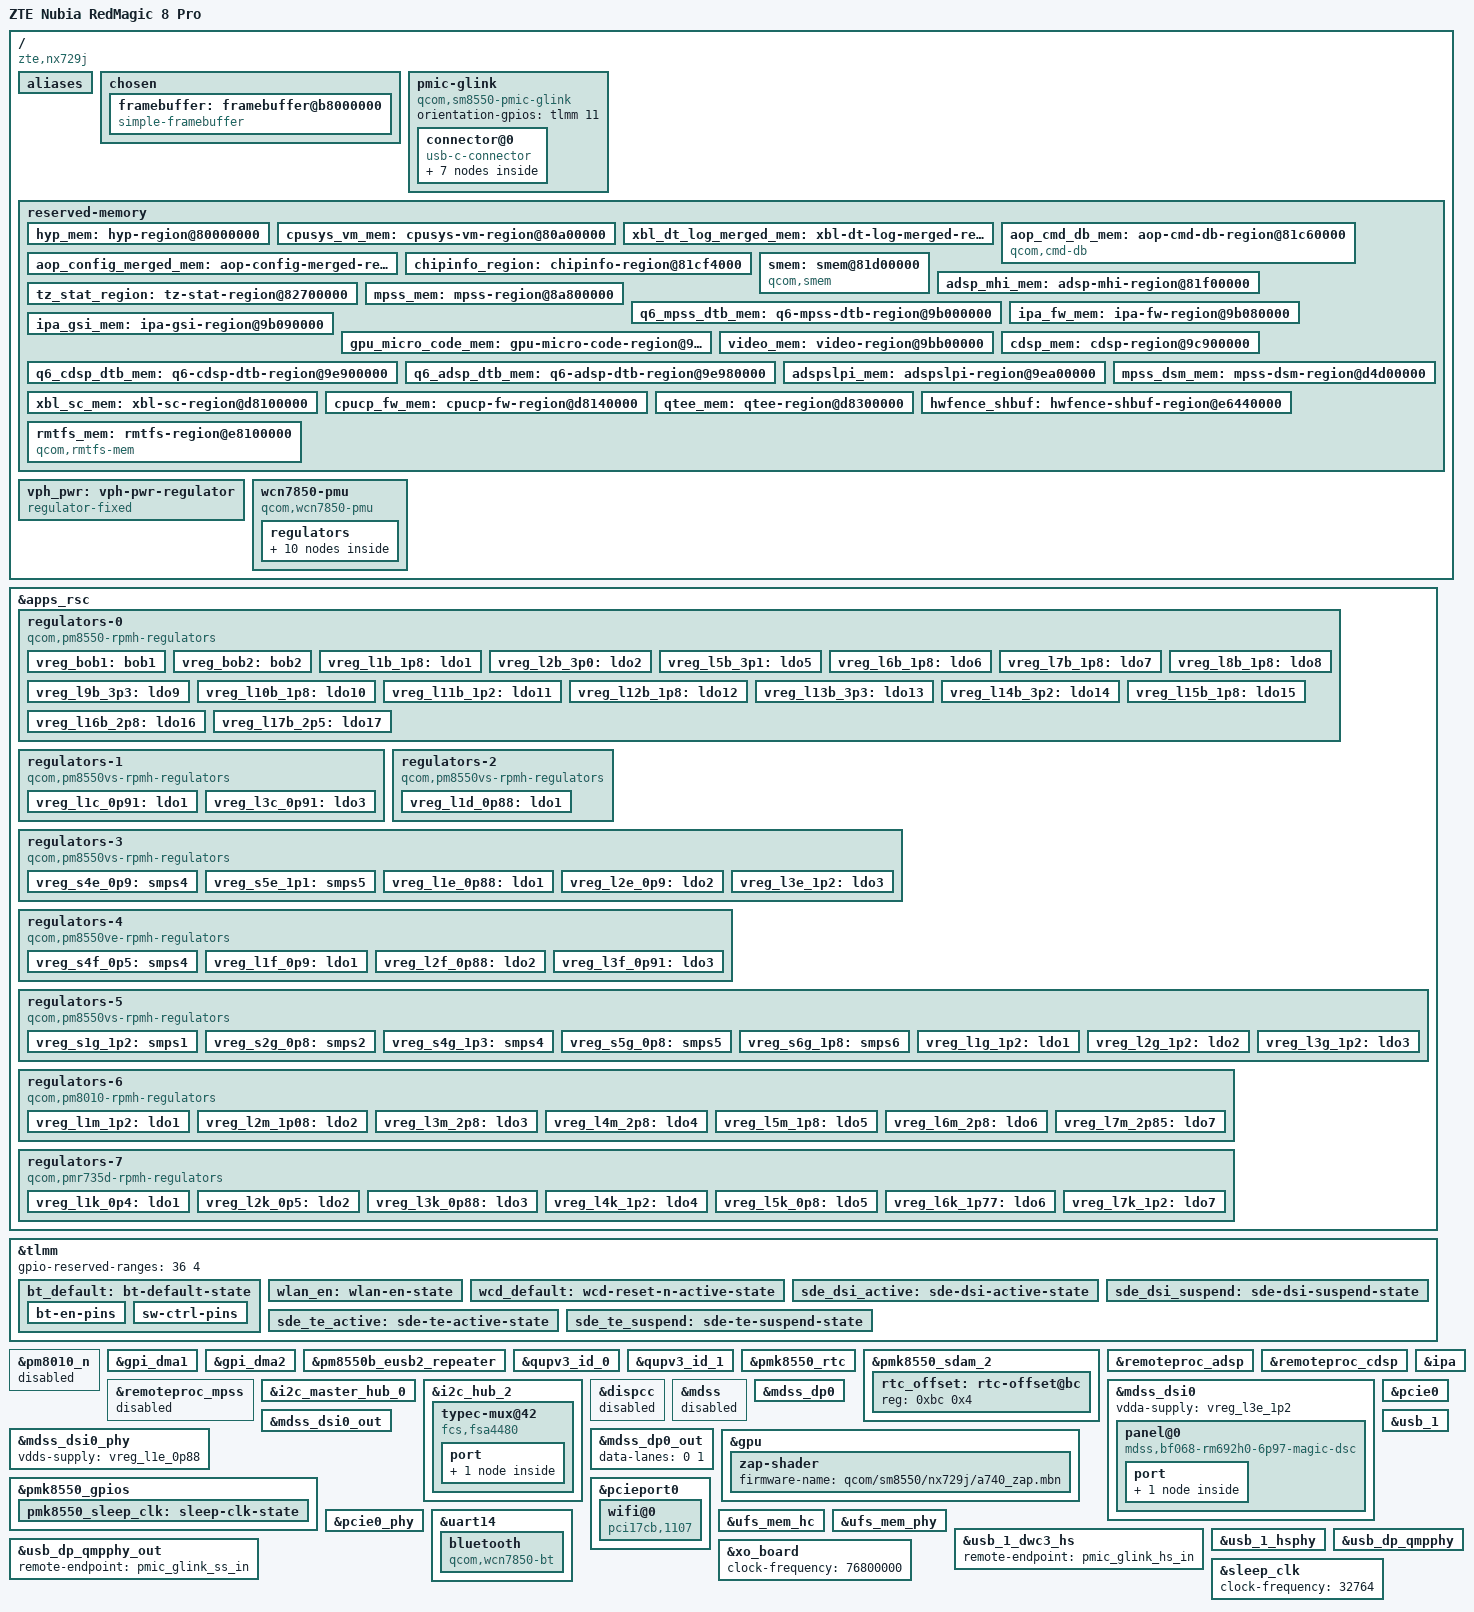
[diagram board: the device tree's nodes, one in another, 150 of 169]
// SPDX-License-Identifier: BSD-3-Clause
/*
 * Copyright (c) 2025, Nika Okromtchedlishvili <okromtchedlishvilinika@gmail.com>
 */
 
/dts-v1/;

#include <dt-bindings/arm/qcom,ids.h>
#include <dt-bindings/leds/common.h>
#include <dt-bindings/regulator/qcom,rpmh-regulator.h>
#include <dt-bindings/input/linux-event-codes.h>
#include <dt-bindings/gpio/gpio.h>
#include <dt-bindings/interrupt-controller/irq.h>

#include "sm8550.dtsi"
#include "pm8010.dtsi"
#include "pm8550.dtsi"
#include "pm8550b.dtsi"
#define PMK8550VE_SID 5
#include "pm8550ve.dtsi"
#include "pm8550vs.dtsi"
#include "pmk8550.dtsi"

/delete-node/ &rmtfs_mem;
/delete-node/ &adspslpi_mem;
/delete-node/ &xbl_dt_log_merged_mem;
/delete-node/ &hwfence_shbuf;

/delete-node/ &hyp_tags_reserved_mem;
/delete-node/ &cdsp_secure_heap_mem;
/delete-node/ &trust_ui_vm_mem;
/delete-node/ &trust_ui_vm_dump;
/delete-node/ &trust_ui_vm_qrtr;
/delete-node/ &trust_ui_vm_vblk0_ring;
/delete-node/ &trust_ui_vm_vblk1_ring;
/delete-node/ &trust_ui_vm_swiotlb;
/delete-node/ &oem_vm_vblk0_ring;
/delete-node/ &oem_vm_swiotlb;
/delete-node/ &oem_vm_mem;
/delete-node/ &hyp_ext_tags_mem;
/delete-node/ &hyp_ext_reserved_mem;

/ {
	model = "ZTE Nubia RedMagic 8 Pro";
	compatible = "zte,nx729j", "qcom,sm8550";
	chassis-type = "handset";
	qcom,msm-id = <0x207 0x20000 0x207 0x10000 0x218 0x20000 0x218 0x10000>;
	qcom,board-id = <0x10008 0>;

	aliases {
		serial0 = &uart7;
		serial1 = &uart14;
	};

	chosen {
		#address-cells = <2>;
		#size-cells = <2>;
		ranges;
		bootargs = "root=/dev/sda15 rootwait rw acpi=off clk_ignore_unused pd_ignore_unused";
		
		framebuffer: framebuffer@b8000000 {
			compatible = "simple-framebuffer";
			reg = <0x0 0xb8000000 0x0 0x2b00000>;
			width = <1116>;
			height = <2480>;
			stride = <(1116 * 4)>;
			format = "a8r8g8b8";
		};
	};

	pmic-glink {
		compatible = "qcom,sm8550-pmic-glink", "qcom,pmic-glink";
		#address-cells = <1>;
		#size-cells = <0>;
		orientation-gpios = <&tlmm 11 GPIO_ACTIVE_HIGH>;

		connector@0 {
			compatible = "usb-c-connector";
			reg = <0>;
			power-role = "dual";
			data-role = "dual";

			ports {
				#address-cells = <1>;
				#size-cells = <0>;

				port@0 {
					reg = <0>;

					pmic_glink_hs_in: endpoint {
						remote-endpoint = <&usb_1_dwc3_hs>;
					};
				};

				port@1 {
					reg = <1>;

					pmic_glink_ss_in: endpoint {
						remote-endpoint = <&usb_dp_qmpphy_out>;
					};
				};

				port@2 {
					reg = <2>;

					pmic_glink_sbu: endpoint {
						remote-endpoint = <&fsa4480_sbu_mux>;
					};
				};
			};
		};
	};

	reserved-memory {
		#address-cells = <2>;
		#size-cells = <2>;
		ranges;
		
		hyp_mem: hyp-region@80000000 {
			no-map;
			reg = <0x00 0x80000000 0x00 0xa00000>;
		};

		cpusys_vm_mem: cpusys-vm-region@80a00000 {
			no-map;
			reg = <0x00 0x80a00000 0x00 0x400000>;
		};

		/* merged xbl_dt_log, xbl_ramdump, aop_image */
		xbl_dt_log_merged_mem: xbl-dt-log-merged-region@81a00000 {
			no-map;
			reg = <0x00 0x81a00000 0x00 0x260000>;
		};

		aop_cmd_db_mem: aop-cmd-db-region@81c60000 {
			compatible = "qcom,cmd-db";
			no-map;
			reg = <0x00 0x81c60000 0x00 0x20000>;
		};

		/* merged aop_config, tme_crash_dump, tme_log, uefi_log */
		aop_config_merged_mem: aop-config-merged-region@81c80000 {
			no-map;
			reg = <0x00 0x81c80000 0x00 0x74000>;
		};
		
		chipinfo_region: chipinfo-region@81cf4000 {
			no-map;
			reg = <0x00 0x81cf4000 0x00 0x1000>;
		};

		/* secdata region can be reused by apps */
		smem: smem@81d00000 {
			no-map;
			reg = <0x00 0x81d00000 0x00 0x200000>;
			hwlocks = <&tcsr_mutex 3>;
			compatible = "qcom,smem";
		};

		adsp_mhi_mem: adsp-mhi-region@81f00000 {
			no-map;
			reg = <0x00 0x81f00000 0x00 0x20000>;
		};
		
		tz_stat_region: tz-stat-region@82700000 {
			no-map;
			reg = <0x00 0x82700000 0x00 0x100000>;
		};
		
		mpss_mem: mpss-region@8a800000 {
			no-map;
			reg = <0x00 0x8a800000 0x00 0x10800000>;
		};

		q6_mpss_dtb_mem: q6-mpss-dtb-region@9b000000 {
			no-map;
			reg = <0x00 0x9b000000 0x00 0x80000>;
		};

		ipa_fw_mem: ipa-fw-region@9b080000 {
			no-map;
			reg = <0x00 0x9b080000 0x00 0x10000>;
		};

		ipa_gsi_mem: ipa-gsi-region@9b090000 {
			no-map;
			reg = <0x00 0x9b090000 0x00 0xa000>;
		};

		gpu_micro_code_mem: gpu-micro-code-region@9b09a000 {
			no-map;
			reg = <0x00 0x9b09a000 0x00 0x2000>;
		};
		
		video_mem: video-region@9bb00000 {
			no-map;
			reg = <0x00 0x9bb00000 0x00 0x700000>;
		};

		cdsp_mem: cdsp-region@9c900000 {
			no-map;
			reg = <0x00 0x9c900000 0x00 0x2000000>;
		};

		q6_cdsp_dtb_mem: q6-cdsp-dtb-region@9e900000 {
			no-map;
			reg = <0x00 0x9e900000 0x00 0x80000>;
		};

		q6_adsp_dtb_mem: q6-adsp-dtb-region@9e980000 {
			no-map;
			reg = <0x00 0x9e980000 0x00 0x80000>;
		};

		adspslpi_mem: adspslpi-region@9ea00000 {
			no-map;
			reg = <0x00 0x9ea00000 0x00 0x4880000>;
		};

		mpss_dsm_mem: mpss-dsm-region@d4d00000 {
			no-map;
			reg = <0x00 0xd4d00000 0x00 0x3300000>;
		};

		xbl_sc_mem: xbl-sc-region@d8100000 {
			no-map;
			reg = <0x00 0xd8100000 0x00 0x40000>;
		};

		cpucp_fw_mem: cpucp-fw-region@d8140000 {
			no-map;
			reg = <0x00 0xd8140000 0x00 0x1c0000>;
		};

		qtee_mem: qtee-region@d8300000 {
			no-map;
			reg = <0x00 0xd8300000 0x00 0x500000>;
		};

		hwfence_shbuf: hwfence-shbuf-region@e6440000 {
			no-map;
			reg = <0x00 0xe6440000 0x00 0x2dd000>;
		};

		rmtfs_mem: rmtfs-region@e8100000 {
			compatible = "qcom,rmtfs-mem";
			reg = <0x0 0xe8100000 0x0 0x280000>;
			no-map;

			qcom,client-id = <1>;
			qcom,vmid = <QCOM_SCM_VMID_MSS_MSA>;
		};
	};

	vph_pwr: vph-pwr-regulator {
		compatible = "regulator-fixed";
		regulator-name = "vph_pwr";
		regulator-min-microvolt = <3700000>;
		regulator-max-microvolt = <3700000>;

		regulator-always-on;
		regulator-boot-on;
	};
	
	wcn7850-pmu {
		compatible = "qcom,wcn7850-pmu";

		pinctrl-names = "default";
		pinctrl-0 = <&wlan_en>, <&bt_default>, <&pmk8550_sleep_clk>;

		wlan-enable-gpios = <&tlmm 80 GPIO_ACTIVE_HIGH>;
		bt-enable-gpios = <&tlmm 81 GPIO_ACTIVE_HIGH>;

		vdd-supply = <&vreg_s5g_0p8>;
		vddio-supply = <&vreg_l15b_1p8>; 
		vddaon-supply = <&vreg_s2g_0p8>;
		vdddig-supply = <&vreg_s4e_0p9>;
		vddrfa1p2-supply = <&vreg_s4g_1p3>;
		vddrfa1p8-supply = <&vreg_s6g_1p8>;

		regulators {
			vreg_pmu_rfa_cmn: ldo0 {
				regulator-name = "vreg_pmu_rfa_cmn";
			};

			vreg_pmu_aon_0p59: ldo1 {
				regulator-name = "vreg_pmu_aon_0p59";
			};

			vreg_pmu_wlcx_0p8: ldo2 {
				regulator-name = "vreg_pmu_wlcx_0p8";
			};

			vreg_pmu_wlmx_0p85: ldo3 {
				regulator-name = "vreg_pmu_wlmx_0p85";
			};

			vreg_pmu_btcmx_0p85: ldo4 {
				regulator-name = "vreg_pmu_btcmx_0p85";
			};

			vreg_pmu_rfa_0p8: ldo5 {
				regulator-name = "vreg_pmu_rfa_0p8";
			};

			vreg_pmu_rfa_1p2: ldo6 {
				regulator-name = "vreg_pmu_rfa_1p2";
			};

			vreg_pmu_rfa_1p8: ldo7 {
				regulator-name = "vreg_pmu_rfa_1p8";
			};

			vreg_pmu_pcie_0p9: ldo8 {
				regulator-name = "vreg_pmu_pcie_0p9";
			};

			vreg_pmu_pcie_1p8: ldo9 {
				regulator-name = "vreg_pmu_pcie_1p8";
			};
		};
	};
};

&apps_rsc {
	regulators-0 {
		compatible = "qcom,pm8550-rpmh-regulators";
		qcom,pmic-id = "b";

		vdd-bob1-supply = <&vph_pwr>;
		vdd-bob2-supply = <&vph_pwr>;
		vdd-l1-l4-l10-supply = <&vreg_s6g_1p8>;
		vdd-l2-l13-l14-supply = <&vreg_bob1>;
		vdd-l3-supply = <&vreg_s4g_1p3>;
		vdd-l5-l16-supply = <&vreg_bob1>;
		vdd-l6-l7-supply = <&vreg_bob1>;
		vdd-l8-l9-supply = <&vreg_bob1>;
		vdd-l11-supply = <&vreg_s4g_1p3>;
		vdd-l12-supply = <&vreg_s6g_1p8>;
		vdd-l15-supply = <&vreg_s6g_1p8>;
		vdd-l17-supply = <&vreg_bob2>;

		vreg_bob1: bob1 {
			regulator-name = "vreg_bob1";
			regulator-min-microvolt = <3008000>;
			regulator-max-microvolt = <3960000>;
			regulator-initial-mode = <RPMH_REGULATOR_MODE_HPM>;
		};

		vreg_bob2: bob2 {
			regulator-name = "vreg_bob2";
			regulator-min-microvolt = <2704000>;
			regulator-max-microvolt = <3008000>;
			regulator-initial-mode = <RPMH_REGULATOR_MODE_HPM>;
		};

		vreg_l1b_1p8: ldo1 {
			regulator-name = "vreg_l1b_1p8";
			regulator-min-microvolt = <1800000>;
			regulator-max-microvolt = <1800000>;
			regulator-initial-mode = <RPMH_REGULATOR_MODE_HPM>;
		};

		vreg_l2b_3p0: ldo2 {
			regulator-name = "vreg_l2b_3p0";
			regulator-min-microvolt = <3008000>;
			regulator-max-microvolt = <3008000>;
			regulator-initial-mode = <RPMH_REGULATOR_MODE_HPM>;
		};

		vreg_l5b_3p1: ldo5 {
			regulator-name = "vreg_l5b_3p1";
			regulator-min-microvolt = <3104000>;
			regulator-max-microvolt = <3104000>;
			regulator-initial-mode = <RPMH_REGULATOR_MODE_HPM>;
		};

		vreg_l6b_1p8: ldo6 {
			regulator-name = "vreg_l6b_1p8";
			regulator-min-microvolt = <1800000>;
			regulator-max-microvolt = <3008000>;
			regulator-initial-mode = <RPMH_REGULATOR_MODE_HPM>;
		};

		vreg_l7b_1p8: ldo7 {
			regulator-name = "vreg_l7b_1p8";
			regulator-min-microvolt = <1800000>;
			regulator-max-microvolt = <3008000>;
			regulator-initial-mode = <RPMH_REGULATOR_MODE_HPM>;
		};

		vreg_l8b_1p8: ldo8 {
			regulator-name = "vreg_l8b_1p8";
			regulator-min-microvolt = <1800000>;
			regulator-max-microvolt = <3008000>;
			regulator-initial-mode = <RPMH_REGULATOR_MODE_HPM>;
			regulator-always-on;
			regulator-boot-on;
		};

		vreg_l9b_3p3: ldo9 {
			regulator-name = "vreg_l9b_3p3";
			regulator-min-microvolt = <2960000>;
			regulator-max-microvolt = <3008000>;
			regulator-initial-mode = <RPMH_REGULATOR_MODE_HPM>;
		};

		vreg_l10b_1p8: ldo10 {
			regulator-name = "vreg_l10b_1p8";
			regulator-min-microvolt = <1800000>;
			regulator-max-microvolt = <1800000>;
			regulator-initial-mode = <RPMH_REGULATOR_MODE_HPM>;
			regulator-always-on;
		};

		vreg_l11b_1p2: ldo11 {
			regulator-name = "vreg_l11b_1p2";
			regulator-min-microvolt = <1200000>;
			regulator-max-microvolt = <1504000>;
			regulator-initial-mode = <RPMH_REGULATOR_MODE_HPM>;
		};

		vreg_l12b_1p8: ldo12 {
			regulator-name = "vreg_l12b_1p8";
			regulator-min-microvolt = <1800000>;
			regulator-max-microvolt = <1800000>;
			regulator-initial-mode = <RPMH_REGULATOR_MODE_HPM>;
		};

		vreg_l13b_3p3: ldo13 {
			regulator-name = "vreg_l13b_3p3";
			regulator-min-microvolt = <3000000>;
			regulator-max-microvolt = <3000000>;
			regulator-initial-mode = <RPMH_REGULATOR_MODE_HPM>;
		};

		vreg_l14b_3p2: ldo14 {
			regulator-name = "vreg_l14b_3p2";
			regulator-min-microvolt = <3200000>;
			regulator-max-microvolt = <3200000>;
			regulator-initial-mode = <RPMH_REGULATOR_MODE_HPM>;
		};
		
		vreg_l15b_1p8: ldo15 {
			regulator-name = "vreg_l15b_1p8";
			regulator-min-microvolt = <1800000>;
			regulator-max-microvolt = <1800000>;
			regulator-initial-mode = <RPMH_REGULATOR_MODE_HPM>;
			regulator-always-on;
		};

		vreg_l16b_2p8: ldo16 {
			regulator-name = "vreg_l16b_2p8";
			regulator-min-microvolt = <2800000>;
			regulator-max-microvolt = <3312000>;
			regulator-initial-mode = <RPMH_REGULATOR_MODE_HPM>;
		};

		vreg_l17b_2p5: ldo17 {
			regulator-name = "vreg_l17b_2p5";
			regulator-min-microvolt = <2504000>;
			regulator-max-microvolt = <2504000>;
			regulator-initial-mode = <RPMH_REGULATOR_MODE_HPM>;
		};
	};

	regulators-1 {
		compatible = "qcom,pm8550vs-rpmh-regulators";
		qcom,pmic-id = "c";

		vdd-l3-supply = <&vreg_s4e_0p9>;
		
		
		vreg_l1c_0p91: ldo1 {
			regulator-name = "vreg_l1c_0p9";
			regulator-min-microvolt = <1200000>;
			regulator-max-microvolt = <1200000>;
			regulator-initial-mode = <RPMH_REGULATOR_MODE_HPM>;
		};

		vreg_l3c_0p91: ldo3 {
			regulator-name = "vreg_l3c_0p9";
			regulator-min-microvolt = <880000>;
			regulator-max-microvolt = <912000>;
			regulator-initial-mode = <RPMH_REGULATOR_MODE_HPM>;
		};
	};

	regulators-2 {
		compatible = "qcom,pm8550vs-rpmh-regulators";
		qcom,pmic-id = "d";

		vdd-l1-supply = <&vreg_s4e_0p9>;

		vreg_l1d_0p88: ldo1 {
			regulator-name = "vreg_l1d_0p88";
			regulator-min-microvolt = <880000>;
			regulator-max-microvolt = <920000>;
			regulator-initial-mode = <RPMH_REGULATOR_MODE_HPM>;
		};
	};

	regulators-3 {
		compatible = "qcom,pm8550vs-rpmh-regulators";
		qcom,pmic-id = "e";

		vdd-l1-supply = <&vreg_s4e_0p9>;
		vdd-l2-supply = <&vreg_s4e_0p9>;
		vdd-l3-supply = <&vreg_s4g_1p3>;
		vdd-s4-supply = <&vph_pwr>;
		vdd-s5-supply = <&vph_pwr>;

		vreg_s4e_0p9: smps4 {
			regulator-name = "vreg_s4e_0p9";
			regulator-min-microvolt = <904000>;
			regulator-max-microvolt = <984000>;
			regulator-initial-mode = <RPMH_REGULATOR_MODE_HPM>;
		};

		vreg_s5e_1p1: smps5 {
			regulator-name = "vreg_s5e_1p1";
			regulator-min-microvolt = <1010000>;
			regulator-max-microvolt = <1120000>;
			regulator-initial-mode = <RPMH_REGULATOR_MODE_HPM>;
		};

		vreg_l1e_0p88: ldo1 {
			regulator-name = "vreg_l1e_0p88";
			regulator-min-microvolt = <880000>;
			regulator-max-microvolt = <912000>;
			regulator-initial-mode = <RPMH_REGULATOR_MODE_HPM>;
		};

		vreg_l2e_0p9: ldo2 {
			regulator-name = "vreg_l2e_0p9";
			regulator-min-microvolt = <870000>;
			regulator-max-microvolt = <970000>;
			regulator-initial-mode = <RPMH_REGULATOR_MODE_HPM>;
		};

		vreg_l3e_1p2: ldo3 {
			regulator-name = "vreg_l3e_1p2";
			regulator-min-microvolt = <1200000>;
			regulator-max-microvolt = <1200000>;
			regulator-initial-mode = <RPMH_REGULATOR_MODE_HPM>;
		};
	};

	regulators-4 {
		compatible = "qcom,pm8550ve-rpmh-regulators";
		qcom,pmic-id = "f";

		vdd-l1-supply = <&vreg_s4e_0p9>;
		vdd-l2-supply = <&vreg_s4e_0p9>;
		vdd-l3-supply = <&vreg_s4e_0p9>;
		vdd-s4-supply = <&vph_pwr>;

		vreg_s4f_0p5: smps4 {
			regulator-name = "vreg_s4f_0p5";
			regulator-min-microvolt = <300000>;
			regulator-max-microvolt = <700000>;
			regulator-initial-mode = <RPMH_REGULATOR_MODE_HPM>;
		};

		vreg_l1f_0p9: ldo1 {
			regulator-name = "vreg_l1f_0p9";
			regulator-min-microvolt = <880000>;
			regulator-max-microvolt = <912000>;
			regulator-initial-mode = <RPMH_REGULATOR_MODE_HPM>;
		};

		vreg_l2f_0p88: ldo2 {
			regulator-name = "vreg_l2f_0p88";
			regulator-min-microvolt = <880000>;
			regulator-max-microvolt = <912000>;
			regulator-initial-mode = <RPMH_REGULATOR_MODE_HPM>;
		};

		vreg_l3f_0p91: ldo3 {
			regulator-name = "vreg_l3f_0p91";
			regulator-min-microvolt = <880000>;
			regulator-max-microvolt = <912000>;
			regulator-initial-mode = <RPMH_REGULATOR_MODE_HPM>;
		};
	};

	regulators-5 {
		compatible = "qcom,pm8550vs-rpmh-regulators";
		qcom,pmic-id = "g";

		vdd-l1-supply = <&vreg_s4g_1p3>;
		vdd-l2-supply = <&vreg_s4g_1p3>;
		vdd-l3-supply = <&vreg_s4g_1p3>;
		vdd-s1-supply = <&vph_pwr>;
		vdd-s2-supply = <&vph_pwr>;
		vdd-s3-supply = <&vph_pwr>;
		vdd-s4-supply = <&vph_pwr>;
		vdd-s5-supply = <&vph_pwr>;
		vdd-s6-supply = <&vph_pwr>;

		vreg_s1g_1p2: smps1 {
			regulator-name = "vreg_s1g_1p2";
			regulator-min-microvolt = <1200000>;
			regulator-max-microvolt = <1300000>;
			regulator-initial-mode = <RPMH_REGULATOR_MODE_HPM>;
		};

		vreg_s2g_0p8: smps2 {
			regulator-name = "vreg_s2g_0p8";
			regulator-min-microvolt = <500000>;
			regulator-max-microvolt = <1036000>;
			regulator-initial-mode = <RPMH_REGULATOR_MODE_HPM>;
		};

		vreg_s4g_1p3: smps4 {
			regulator-name = "vreg_s4g_1p3";
			regulator-min-microvolt = <1200000>;
			regulator-max-microvolt = <1352000>;
			regulator-initial-mode = <RPMH_REGULATOR_MODE_HPM>;
		};

		vreg_s5g_0p8: smps5 {
			regulator-name = "vreg_s5g_0p8";
			regulator-min-microvolt = <500000>;
			regulator-max-microvolt = <1004000>;
			regulator-initial-mode = <RPMH_REGULATOR_MODE_HPM>;
		};

		vreg_s6g_1p8: smps6 {
			regulator-name = "vreg_s6g_1p8";
			regulator-min-microvolt = <1800000>;
			regulator-max-microvolt = <2000000>;
			regulator-initial-mode = <RPMH_REGULATOR_MODE_HPM>;
		};

		vreg_l1g_1p2: ldo1 {
			regulator-name = "vreg_l1g_1p2";
			regulator-min-microvolt = <1144000>;
			regulator-max-microvolt = <1256000>;
			regulator-initial-mode = <RPMH_REGULATOR_MODE_HPM>;
		};

		vreg_l2g_1p2: ldo2 {
			regulator-name = "vreg_l2g_1p2";
			regulator-min-microvolt = <1100000>;
			regulator-max-microvolt = <1200000>;
			regulator-initial-mode = <RPMH_REGULATOR_MODE_HPM>;
		};

		vreg_l3g_1p2: ldo3 {
			regulator-name = "vreg_l3g_1p2";
			regulator-min-microvolt = <1200000>;
			regulator-max-microvolt = <1200000>;
			regulator-initial-mode = <RPMH_REGULATOR_MODE_HPM>;
		};
	};

	regulators-6 {
		compatible = "qcom,pm8010-rpmh-regulators";
		qcom,pmic-id = "m";

		vdd-l1-l2-supply = <&vreg_s4g_1p3>;
		vdd-l3-l4-supply = <&vreg_bob2>;
		vdd-l5-supply = <&vreg_s6g_1p8>;
		vdd-l6-supply = <&vreg_s6g_1p8>;
		vdd-l7-supply = <&vreg_bob1>;

		vreg_l1m_1p2: ldo1 {
			regulator-name = "vreg_l1m_1p2";
			regulator-min-microvolt = <920000>;
			regulator-max-microvolt = <1056000>;
			regulator-initial-mode = <RPMH_REGULATOR_MODE_HPM>;
		};

		vreg_l2m_1p08: ldo2 {
			regulator-name = "vreg_l2m_1p08";
			regulator-min-microvolt = <1056000>;
			regulator-max-microvolt = <1200000>;
			regulator-initial-mode = <RPMH_REGULATOR_MODE_HPM>;
		};

		vreg_l3m_2p8: ldo3 {
			regulator-name = "vreg_l3m_2p8";
			regulator-min-microvolt = <2800000>;
			regulator-max-microvolt = <2800000>;
			regulator-initial-mode = <RPMH_REGULATOR_MODE_HPM>;
		};

		vreg_l4m_2p8: ldo4 {
			regulator-name = "vreg_l4m_2p8";
			regulator-min-microvolt = <1800000>;
			regulator-max-microvolt = <2800000>;
			regulator-initial-mode = <RPMH_REGULATOR_MODE_HPM>;
		};

		vreg_l5m_1p8: ldo5 {
			regulator-name = "vreg_l5m_1p8";
			regulator-min-microvolt = <1800000>;
			regulator-max-microvolt = <1800000>;
			regulator-initial-mode = <RPMH_REGULATOR_MODE_HPM>;
		};

		vreg_l6m_2p8: ldo6 {
			regulator-name = "vreg_l6m_2p8";
			regulator-min-microvolt = <2800000>;
			regulator-max-microvolt = <2800000>;
			regulator-initial-mode = <RPMH_REGULATOR_MODE_HPM>;
		};

		vreg_l7m_2p85: ldo7 {
			regulator-name = "vreg_l7m_2p85";
			regulator-min-microvolt = <2800000>;
			regulator-max-microvolt = <2904000>;
			regulator-initial-mode = <RPMH_REGULATOR_MODE_HPM>;
		};
	};

	regulators-7 {
		compatible = "qcom,pmr735d-rpmh-regulators";
		qcom,pmic-id = "k";

		vdd-l1-l2-l5-supply = <&vreg_s2g_0p8>;
		vdd-l3-l4-supply = <&vreg_s1g_1p2>;
		vdd-l6-supply  = <&vreg_s6g_1p8>;
		vdd-l7-supply = <&vreg_s1g_1p2>;

		vreg_l1k_0p4: ldo1 {
			regulator-name = "vreg_l1k_0p4";
			regulator-min-microvolt = <400000>;
			regulator-max-microvolt = <900000>;
			regulator-initial-mode = <RPMH_REGULATOR_MODE_HPM>;
		};

		vreg_l2k_0p5: ldo2 {
			regulator-name = "vreg_l2k_0p5";
			regulator-min-microvolt = <500000>;
			regulator-max-microvolt = <900000>;
			regulator-initial-mode = <RPMH_REGULATOR_MODE_HPM>;
		};

		vreg_l3k_0p88: ldo3 {
			regulator-name = "vreg_l3k_0p88";
			regulator-min-microvolt = <880000>;
			regulator-max-microvolt = <912000>;
			regulator-initial-mode = <RPMH_REGULATOR_MODE_HPM>;
		};

		vreg_l4k_1p2: ldo4 {
			regulator-name = "vreg_l4k_1p2";
			regulator-min-microvolt = <1200000>;
			regulator-max-microvolt = <1200000>;
			regulator-initial-mode = <RPMH_REGULATOR_MODE_HPM>;
		};

		vreg_l5k_0p8: ldo5 {
			regulator-name = "vreg_l5k_0p8";
			regulator-min-microvolt = <800000>;
			regulator-max-microvolt = <800000>;
			regulator-initial-mode = <RPMH_REGULATOR_MODE_HPM>;
		};

		vreg_l6k_1p77: ldo6 {
			regulator-name = "vreg_l6k_1p77";
			regulator-min-microvolt = <1776000>;
			regulator-max-microvolt = <1900000>;
			regulator-initial-mode = <RPMH_REGULATOR_MODE_HPM>;
		};

		vreg_l7k_1p2: ldo7 {
			regulator-name = "vreg_l7k_1p2";
			regulator-min-microvolt = <1200000>;
			regulator-max-microvolt = <1200000>;
			regulator-initial-mode = <RPMH_REGULATOR_MODE_HPM>;
		};
	};
};

&tlmm {
	gpio-reserved-ranges = <36 4>;

	bt_default: bt-default-state {
		bt-en-pins {
			pins = "gpio81";
			function = "gpio";
			drive-strength = <16>;
			bias-disable;
		};

		sw-ctrl-pins {
			pins = "gpio82";
			function = "gpio";
			bias-pull-down;
		};
	};

	wlan_en: wlan-en-state {
		pins = "gpio80";
		function = "gpio";
		drive-strength = <8>;
		bias-pull-down;
	};

	wcd_default: wcd-reset-n-active-state {
		pins = "gpio108";
		function = "gpio";
		drive-strength = <16>;
		bias-disable;
		output-low;
	};
	
	sde_dsi_active: sde-dsi-active-state {
		pins = "gpio133";
		function = "gpio";
		drive-strength = <8>;
		bias-disable;
	};

	sde_dsi_suspend: sde-dsi-suspend-state {
		pins = "gpio133";
		function = "gpio";
		drive-strength = <2>;
		bias-pull-down;
	};

	sde_te_active: sde-te-active-state {
		pins = "gpio86";
		function = "mdp_vsync";
		drive-strength = <2>;
		bias-pull-down;
	};

	sde_te_suspend: sde-te-suspend-state {
		pins = "gpio86";
		function = "mdp_vsync";
		drive-strength = <2>;
		bias-pull-down;
	};
};

&pm8010_n {
	status = "disabled";
};

&gpi_dma1 {
	status = "okay";
};

&gpi_dma2 {
	status = "okay";
};

&pm8550b_eusb2_repeater {
	vdd18-supply = <&vreg_l15b_1p8>;
	vdd3-supply = <&vreg_l5b_3p1>;
};

&qupv3_id_0 {
	status = "okay";
};

&qupv3_id_1 {
	status = "okay";
};

&pmk8550_rtc {
	nvmem-cells = <&rtc_offset>;
	nvmem-cell-names = "offset";
};

&pmk8550_sdam_2 {
	rtc_offset: rtc-offset@bc {
		reg = <0xbc 0x4>;
	};
};

&remoteproc_adsp {
	firmware-name = "qcom/sm8550/nx729j/adsp.mbn",
			"qcom/sm8550/nx729j/adsp_dtb.mbn";
	status = "okay";
};

&remoteproc_cdsp {
	firmware-name = "qcom/sm8550/nx729j/cdsp.mbn",
			"qcom/sm8550/nx729j/cdsp_dtb.mbn";
	status = "okay";
};

&remoteproc_mpss {
	firmware-name = "qcom/sm8550/nx729j/modem.mbn",
			"qcom/sm8550/nx729j/modem_dtb.mbn";
	status = "disabled";
};

&i2c_master_hub_0 {
	status = "okay";
};

&i2c_hub_2 {
	status = "okay";

	typec-mux@42 {
		compatible = "fcs,fsa4480";
		reg = <0x42>;

		vcc-supply = <&vreg_bob1>;

		mode-switch;
		orientation-switch;

		port {
			fsa4480_sbu_mux: endpoint {
				remote-endpoint = <&pmic_glink_sbu>;
			};
		};
	};
};

&dispcc {
	status = "disabled";
};

&mdss {
	status = "disabled";
};

&mdss_dsi0 {
	vdda-supply = <&vreg_l3e_1p2>;
	status = "okay";
	
	panel@0 {
		compatible = "mdss,bf068-rm692h0-6p97-magic-dsc";
		reg = <0>;
		
		pinctrl-names = "default", "sleep";
		pinctrl-0 = <&sde_dsi_active>, <&sde_te_active>;
		pinctrl-1 = <&sde_dsi_suspend>, <&sde_te_suspend>;

		vddio-supply = <&vreg_l12b_1p8>;
		vci-supply = <&vreg_l13b_3p3>;
		
		reset-gpios = <&tlmm 133 GPIO_ACTIVE_LOW>;

		port {
			panel_in: endpoint {
				remote-endpoint = <&mdss_dsi0_out>;
			};
		};
	};
};

&mdss_dsi0_out {
	status = "okay";
	data-lanes = <0 1 2 3>;
	remote-endpoint = <&panel_in>;
};

&mdss_dsi0_phy {
	vdds-supply = <&vreg_l1e_0p88>;
	status = "okay";
};

&mdss_dp0 {
	status = "okay";
};

&mdss_dp0_out {
	data-lanes = <0 1>;
};

&ipa {
	qcom,gsi-loader = "self";
	memory-region = <&ipa_fw_mem>;
	firmware-name = "qcom/sm8550/nx729j/ipa_fws.mbn";
	status = "okay";
};

&gpu {
	status = "okay";

	zap-shader {
		firmware-name = "qcom/sm8550/nx729j/a740_zap.mbn";
	};
};

&pmk8550_gpios {
	pmk8550_sleep_clk: sleep-clk-state {
		pins = "gpio3";
		function = "func1";
		input-disable;
		output-enable;
		bias-disable;
		power-source = <0>;
	};
};

&pcie0 {
	wake-gpios = <&tlmm 96 GPIO_ACTIVE_HIGH>;
	perst-gpios = <&tlmm 94 GPIO_ACTIVE_LOW>;

	pinctrl-names = "default";
	pinctrl-0 = <&pcie0_default_state>;

	status = "okay";
};

&pcieport0 {
	status = "okay";
	
	wifi@0 {
		compatible = "pci17cb,1107";
		reg = <0x10000 0x0 0x0 0x0 0x0>;

		vddrfacmn-supply = <&vreg_pmu_rfa_cmn>;
		vddaon-supply = <&vreg_pmu_aon_0p59>;
		vddwlcx-supply = <&vreg_pmu_wlcx_0p8>;
		vddwlmx-supply = <&vreg_pmu_wlmx_0p85>;
		vddrfa0p8-supply = <&vreg_pmu_rfa_0p8>;
		vddrfa1p2-supply = <&vreg_pmu_rfa_1p2>;
		vddrfa1p8-supply = <&vreg_pmu_rfa_1p8>;
		vddpcie0p9-supply = <&vreg_pmu_pcie_0p9>;
		vddpcie1p8-supply = <&vreg_pmu_pcie_1p8>;
		status = "okay";
	};
};

&pcie0_phy {
	vdda-phy-supply = <&vreg_l1e_0p88>;
	vdda-pll-supply = <&vreg_l3e_1p2>;

	status = "okay";
};

&uart14 {
	status = "okay";

	bluetooth {
		compatible = "qcom,wcn7850-bt";

		local-bd-address = [ c2 59 96 e0 ca 00 ];

		vddrfacmn-supply = <&vreg_pmu_rfa_cmn>;
		vddaon-supply = <&vreg_pmu_aon_0p59>;
		vddwlcx-supply = <&vreg_pmu_wlcx_0p8>;
		vddwlmx-supply = <&vreg_pmu_wlmx_0p85>;
		vddrfa0p8-supply = <&vreg_pmu_rfa_0p8>;
		vddrfa1p2-supply = <&vreg_pmu_rfa_1p2>;
		vddrfa1p8-supply = <&vreg_pmu_rfa_1p8>;

		max-speed = <3200000>;
	};
};

&ufs_mem_hc {
	reset-gpios = <&tlmm 210 GPIO_ACTIVE_LOW>;
	vcc-supply = <&vreg_l17b_2p5>;
	vcc-max-microamp = <1300000>;
	vccq-supply = <&vreg_l1g_1p2>;
	vccq-max-microamp = <1200000>;
	vdd-hba-supply = <&vreg_l3g_1p2>;

	status = "okay";
};

&ufs_mem_phy {
	vdda-phy-supply = <&vreg_l1d_0p88>;
	vdda-pll-supply = <&vreg_l3e_1p2>;

	status = "okay";
};

&usb_1 {
	status = "okay";
};

&usb_1_dwc3_hs {
	remote-endpoint = <&pmic_glink_hs_in>;
};

&usb_1_hsphy {
	vdd-supply = <&vreg_l1e_0p88>;
	vdda12-supply = <&vreg_l3e_1p2>;

	phys = <&pm8550b_eusb2_repeater>;
	status = "okay";
};

&usb_dp_qmpphy {
	vdda-phy-supply = <&vreg_l3e_1p2>;
	vdda-pll-supply = <&vreg_l3f_0p91>;

	status = "okay";
};

&usb_dp_qmpphy_out {
	remote-endpoint = <&pmic_glink_ss_in>;
};

&xo_board {
	clock-frequency = <76800000>;
};

&sleep_clk {
	clock-frequency = <32764>;
};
